# cxd5602 register map
Vendor: Sony Semiconductor Solutions; Series: CXD56xx; File version: 1.0
CPU: CM4 r0p1, little endian, MPU, FPU, 3 interrupt priority bits, 144 interrupts
Registers are 32-bit, read-write, reset 0x0 unless marked. A register's access mark holds for its fields unless they carry their own. Offsets are from the block's base; [hi:lo] are bit positions; {n}, {i} and the like mark numbered series; 'fields as' and 'values as' point back to an identical list.

## UART1 — UART
Base 0x041AC000
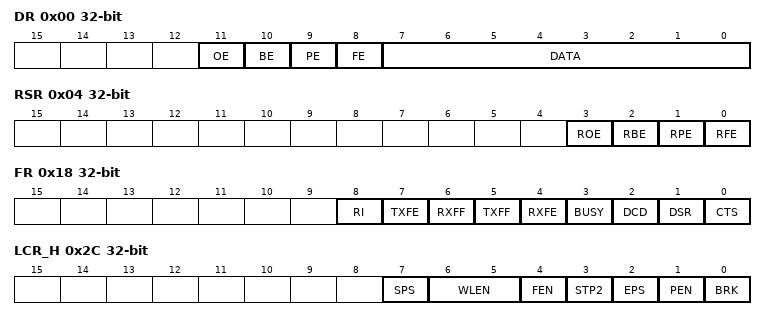
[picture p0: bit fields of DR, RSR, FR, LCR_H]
0x00 DR
  [11] OE ro — Overrun Error
    0=None (no error); 1=Error
  [10] BE ro — Break Error
    0=None (no error); 1=Error
  [9] PE ro — Parity Error
    0=None (no error); 1=Error
  [8] FE ro — Framing Error
    0=None (no error); 1=Error
  [7:0] DATA read-modifies
0x04 RSR ro — Receive Status and Clear Register
  [all] fields
    0=None (no error); 1=Error
  [3] ROE — Overrun Error
  [2] RBE — Break Error
  [1] RPE — Parity Error
  [0] RFE — Framing Error
0x18 FR ro — Flags Register
  [8] RI — Ring Indicator
  [7] TXFE — Transmit FIFO empty
  [6] RXFF — Receive FIFO full
  [5] TXFF — Transmit FIFO full
  [4] RXFE — Receive FIFO empty
  [3] BUSY — UART busy
  [2] DCD — Data carrier detect
  [1] DSR — Data set ready
  [0] CTS — Clear to send
0x20 ILPR — IrDA Low-Power Counter Register
  [7:0] ILPDVSR — 8-bit low-power divisor value
0x24 IBRD — The integer part of the baud rate divisor
  [15:0] BAUD_DIVINT — The integer baud rate divisor
0x28 FBRD — The fractional part of the baud rate divisor
  [5:0] BAUD_DIVFRAC — The fractional baud rate divisor
0x2C LCR_H — Line Control Register
  [7] SPS — Stick parity select
    0=Disabled; 1=Enabled
  [6:5] WLEN — Word Length
    {v}={v+5}bits (v=0..3)
  [4] FEN — Enable FIFOs
    0=Disabled; 1=Enabled
  [3] STP2 — Two stop bits select
    0=NotSelected; 1=Selected
  [2] EPS — Even parity select
    0=OddParity; 1=EvenParity
  [1] PEN — Parity enable
    0=Disabled; 1=Enabled
  [0] BRK — Send break
    0=NormalOps (Normal operation); 1=SendBreak
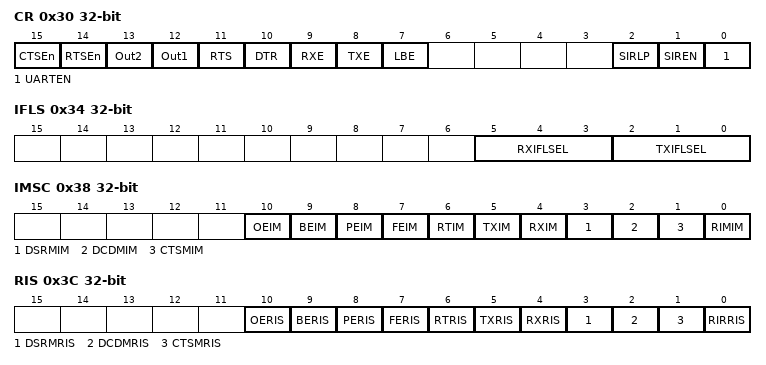
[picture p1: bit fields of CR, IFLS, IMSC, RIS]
0x30 CR — Control Register
  [15] CTSEn — CTS hardware flow control enable
    0=Disabled; 1=Enabled
  [14] RTSEn — RTS hardware flow control enable
    0=Disabled; 1=Enabled
  [13] Out2 — nUARTOut2 modem status
    0=Zero (Output zero); 1=One (Output one)
  [12] Out1 — nUARTOut1 modem status
    0=Zero (Output zero); 1=One (Output one)
  [11] RTS — Request to send
    0=LOW; 1=HIGH
  [10] DTR — Data transmit ready
    0=LOW; 1=HIGH
  [9] RXE — Receive enable
    0=Disabled; 1=Enabled
  [8] TXE — Transmit enable
    0=Disabled; 1=Enabled
  [7] LBE — Loopback enable
    0=Disabled; 1=Enabled
  [2] SIRLP — SIR low-power IrDA
    0=Normal; 1=LowPower
  [1] SIREN — SIR enable
    0=Disabled; 1=Enabled
  [0] UARTEN — UART enable
    0=Disabled; 1=Enabled
0x34 IFLS — Interrupt FIFO Level Select Register
  [5:3] RXIFLSEL — Receive interrupt FIFO level select
    0=FIFO_1_8_FULL (Receive FIFO becomes >= 1/8 full); 1=FIFO_1_4_FULL (Receive FIFO becomes >= 1/4 full); 2=FIFO_1_2_FULL (Receive FIFO becomes >= 1/2 full); 3=FIFO_3_4_FULL (Receive FIFO becomes >= 3/4 full); 4=FIFO_7_8_FULL (Receive FIFO becomes >= 7/8 full)
  [2:0] TXIFLSEL — Transmit interrupt FIFO level select
    values as RXIFLSEL
0x38 IMSC — Interrupt Mask Set and Clear Register
  [10] OEIM — Overrun error interrupt mask
  [9] BEIM — Break error interrupt mask
  [8] PEIM — Parity error interrupt mask
  [7] FEIM — Framing error interrupt mask
  [6] RTIM — Receive timeout interrupt mask
  [5] TXIM — Transmit interrupt mask
  [4] RXIM — Receive interrupt mask
  [3] DSRMIM — nUARTDSR modem interrupt mask
  [2] DCDMIM — nUARTDCD modem interrupt mask
  [1] CTSMIM — nUARTCTS modem interrupt mask
  [0] RIMIM — nUARTRI modem interrupt mask
0x3C RIS ro — Raw Interrupt Status Register
  [10] OERIS — Overrun error interrupt status
  [9] BERIS — Break error interrupt status
  [8] PERIS — Parity error interrupt status
  [7] FERIS — Framing error interrupt status
  [6] RTRIS — Receive timeout interrupt status
  [5] TXRIS — Transmit interrupt status
  [4] RXRIS — Receive interrupt status
  [3] DSRMRIS — nUARTDSR modem interrupt status
  [2] DCDMRIS — nUARTDCD modem interrupt status
  [1] CTSMRIS — nUARTCTS modem interrupt status
  [0] RIRRIS — nUARTRI modem interrupt status
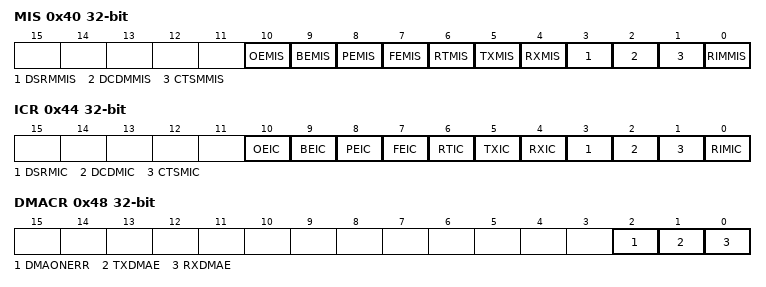
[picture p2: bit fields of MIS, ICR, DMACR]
0x40 MIS ro — Masked Interrupt Status Register
  [10] OEMIS — Overrun error masked interrupt status
  [9] BEMIS — Break error masked interrupt status
  [8] PEMIS — Parity error masked interrupt status
  [7] FEMIS — Framing error masked interrupt status
  [6] RTMIS — Receive timeout masked interrupt status
  [5] TXMIS — Transmit masked interrupt status
  [4] RXMIS — Receive masked interrupt status
  [3] DSRMMIS — nUARTDSR modem masked interrupt status
  [2] DCDMMIS — nUARTDCD modem masked interrupt status
  [1] CTSMMIS — nUARTCTS modem masked interrupt status
  [0] RIMMIS — nUARTRI modem masked interrupt status
0x44 ICR wo — Interrupt Clear Register
  [10] OEIC — Overrun error interrupt clear
  [9] BEIC — Break error interrupt clear
  [8] PEIC — Parity error interrupt clear
  [7] FEIC — Framing error interrupt clear
  [6] RTIC — Receive timeout interrupt clear
  [5] TXIC — Transmit interrupt clear
  [4] RXIC — Receive interrupt clear
  [3] DSRMIC — nUARTDSR modem interrupt clear
  [2] DCDMIC — nUARTDCD modem interrupt clear
  [1] CTSMIC — nUARTCTS modem interrupt clear
  [0] RIMIC — nUARTRI modem interrupt clear
0x48 DMACR — DMA Control Regsiter
  [2] DMAONERR — DMA on error
  [1] TXDMAE — Transmit DMA enable
    0=Disabled; 1=Enabled
  [0] RXDMAE — Receive DMA enable
    0=Disabled; 1=Enabled

## UART2 — UART
Base 0x02103000
Registers as UART1; these are added or differ:
0x1C RTO — Receive Timeout Configuration Register
  [15:0] TIMEOUT — Recieve timeout
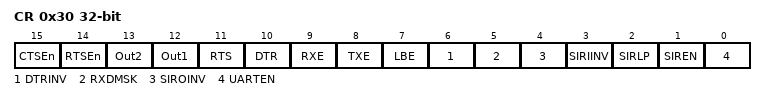
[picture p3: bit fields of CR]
0x30 CR — Control Register
  [15] CTSEn — CTS hardware flow control enable
    0=Disabled; 1=Enabled
  [14] RTSEn — RTS hardware flow control enable
    0=Disabled; 1=Enabled
  [13] Out2 — nUARTOut2 modem status
    0=Zero (Output zero); 1=One (Output one)
  [12] Out1 — nUARTOut1 modem status
    0=Zero (Output zero); 1=One (Output one)
  [11] RTS — Request to send
    0=LOW; 1=HIGH
  [10] DTR — Data transmit ready
    0=LOW; 1=HIGH
  [9] RXE — Receive enable
    0=Disabled; 1=Enabled
  [8] TXE — Transmit enable
    0=Disabled; 1=Enabled
  [7] LBE — Loopback enable
    0=Disabled; 1=Enabled
  [6] DTRINV — Invert DTR signal
    0=Normal; 1=Inverted
  [5] RXDMSK — RxD mask
    0=Normal; 1=ForceOne (Force 1)
  [4] SIROINV — Invert SIR output
    0=Normal; 1=Inverted
  [3] SIRIINV — Invert SIR input
    0=Normal; 1=Inverted
  [2] SIRLP — SIR low-power IrDA
    0=Normal; 1=LowPower
  [1] SIREN — SIR enable
    0=Disabled; 1=Enabled
  [0] UARTEN — UART enable
    0=Disabled; 1=Enabled
